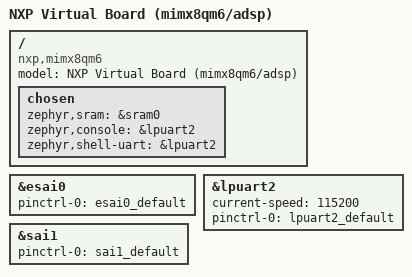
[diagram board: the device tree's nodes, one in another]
/* Auto-generated by gen_nxp_virtual_board.py */
/* Master DTS template: boards/nxp/imx8qm_mek/imx8qm_mek_mimx8qm6_adsp.dts */
/*
 * Copyright (c) 2021, 2024-2025 NXP
 *
 * SPDX-License-Identifier: Apache-2.0
 */

/dts-v1/;

#include <nxp/nxp_imx8qm.dtsi>
#include "imx8qm_mek_mimx8qm6_adsp-pinctrl.dtsi"

/ {
	model = "NXP Virtual Board (mimx8qm6/adsp)";
	compatible = "nxp,mimx8qm6";

	chosen {
		zephyr,sram = &sram0;
		zephyr,console = &lpuart2;
		zephyr,shell-uart = &lpuart2;
	};
};

&esai0 {
	pinctrl-0 = <&esai0_default>;
	pinctrl-names = "default";
};

&lpuart2 {
	status = "okay";
	current-speed = <115200>;
	pinctrl-0 = <&lpuart2_default>;
	pinctrl-names = "default";
};

&sai1 {
	pinctrl-0 = <&sai1_default>;
	pinctrl-names = "default";
};
